# ESP32-S3 register map
Vendor: ESPRESSIF SYSTEMS (SHANGHAI) CO., LTD.; Series: ESP32 S-Series; File version: 22
CPU: Xtensa LX7 r0p0, little endian, no MPU, FPU, 0 interrupt priority bits
Address unit: 32 bits
Registers are 32-bit, read-write, reset 0x0 unless marked. A register's access mark holds for its fields unless they carry their own. Offsets are from the block's base; [hi:lo] are bit positions; {n}, {i} and the like mark numbered series.

## GPIO — General Purpose Input/Output
Base 0x60004000
0x00 BT_SELECT — GPIO bit select register
  [31:0] BT_SEL
0x04 OUT — GPIO output register for GPIO0-31
  [31:0] DATA_ORIG
0x08 OUT_W1TS wo — GPIO output set register for GPIO0-31
0x0C OUT_W1TC wo — GPIO output clear register for GPIO0-31
0x10 OUT1 — GPIO output register for GPIO32-53
  [21:0] DATA_ORIG
0x14 OUT1_W1TS wo — GPIO output set register for GPIO32-53
  [21:0] OUT1_W1TS
0x18 OUT1_W1TC wo — GPIO output clear register for GPIO32-53
  [21:0] OUT1_W1TC
0x1C SDIO_SELECT — GPIO sdio select register
  [7:0] SDIO_SEL
0x20 ENABLE — GPIO output enable register for GPIO0-31
  [31:0] DATA
0x24 ENABLE_W1TS wo — GPIO output enable set register for GPIO0-31
0x28 ENABLE_W1TC wo — GPIO output enable clear register for GPIO0-31
0x2C ENABLE1 — GPIO output enable register for GPIO32-53
  [21:0] DATA
0x30 ENABLE1_W1TS wo — GPIO output enable set register for GPIO32-53
  [21:0] ENABLE1_W1TS
0x34 ENABLE1_W1TC wo — GPIO output enable clear register for GPIO32-53
  [21:0] ENABLE1_W1TC
0x38 STRAP ro — pad strapping register
  [15:0] STRAPPING
0x3C IN ro — GPIO input register for GPIO0-31
  [31:0] DATA_NEXT
0x40 IN1 ro — GPIO input register for GPIO32-53
  [21:0] DATA_NEXT
0x44 STATUS — GPIO interrupt status register for GPIO0-31
  [31:0] INTERRUPT
0x48 STATUS_W1TS wo — GPIO interrupt status set register for GPIO0-31
0x4C STATUS_W1TC wo — GPIO interrupt status clear register for GPIO0-31
0x50 STATUS1 — GPIO interrupt status register for GPIO32-53
  [21:0] INTERRUPT
0x54 STATUS1_W1TS wo — GPIO interrupt status set register for GPIO32-53
  [21:0] STATUS1_W1TS
0x58 STATUS1_W1TC wo — GPIO interrupt status clear register for GPIO32-53
  [21:0] STATUS1_W1TC
0x5C PCPU_INT ro — GPIO PRO_CPU interrupt status register for GPIO0-31
  [31:0] PROCPU_INT
0x60 PCPU_NMI_INT ro — GPIO PRO_CPU(not shielded) interrupt status register for GPIO0-31
  [31:0] PROCPU_NMI_INT
0x64 CPUSDIO_INT ro — GPIO CPUSDIO interrupt status register for GPIO0-31
  [31:0] SDIO_INT
0x68 PCPU_INT1 ro — GPIO PRO_CPU interrupt status register for GPIO32-53
  [21:0] PROCPU_INT1
0x6C PCPU_NMI_INT1 ro — GPIO PRO_CPU(not shielded) interrupt status register for GPIO32-53
  [21:0] PROCPU_NMI_INT1
0x70 CPUSDIO_INT1 ro — GPIO CPUSDIO interrupt status register for GPIO32-53
  [21:0] SDIO_INT1
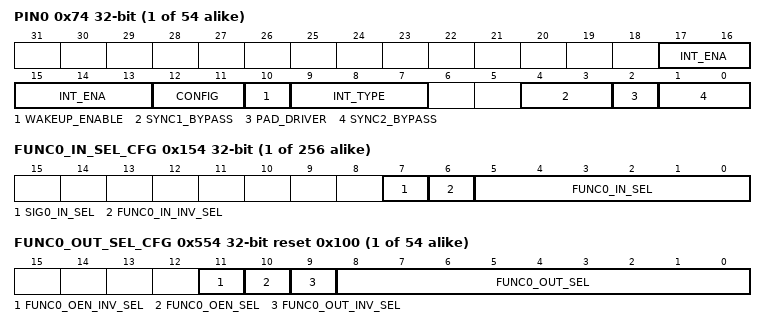
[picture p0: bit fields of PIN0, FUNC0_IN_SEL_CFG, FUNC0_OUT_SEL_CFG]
{0x74+4i} PIN{i} (i=0..53) — GPIO pin configuration register
  [17:13] INT_ENA — set bit 13 to enable CPU interrupt. set bit 14 to enable CPU(not shielded) interrupt.
  [12:11] CONFIG — reserved
  [10] WAKEUP_ENABLE — set this bit to enable GPIO wakeup.(can only wakeup CPU from Light-sleep Mode)
  [9:7] INT_TYPE — set this value to choose interrupt mode. 0:disable GPIO interrupt. 1:trigger at posedge. 2:trigger at negedge. 3:trigger at any edge. 4:valid at low level. 5:valid at high level
  [4:3] SYNC1_BYPASS — set GPIO input_sync1 signal mode. 0:disable. 1:trigger at negedge. 2or3:trigger at posedge.
  [2] PAD_DRIVER — set this bit to select pad driver. 1:open-drain. 0:normal.
  [1:0] SYNC2_BYPASS — set GPIO input_sync2 signal mode. 0:disable. 1:trigger at negedge. 2or3:trigger at posedge.
0x14C STATUS_NEXT ro — GPIO interrupt source register for GPIO0-31
  [31:0] STATUS_INTERRUPT_NEXT
0x150 STATUS_NEXT1 ro — GPIO interrupt source register for GPIO32-53
  [21:0] STATUS_INTERRUPT_NEXT1
{0x154+4i} FUNC{i}_IN_SEL_CFG (i=0..255) — GPIO input function configuration register
  [7] SIG{i}_IN_SEL — set this bit to bypass GPIO. 1:do not bypass GPIO. 0:bypass GPIO.
  [6] FUNC{i}_IN_INV_SEL — set this bit to invert input signal. 1:invert. 0:not invert.
  [5:0] FUNC{i}_IN_SEL — set this value: s=0-53: connect GPIO[s] to this port. s=0x38: set this port always high level. s=0x3C: set this port always low level.
{0x554+4i} FUNC{i}_OUT_SEL_CFG reset 0x100 (i=0..53) — GPIO output function select register
  [11] FUNC{i}_OEN_INV_SEL — set this bit to invert output enable signal.1:invert.0:not invert.
  [10] FUNC{i}_OEN_SEL — set this bit to select output enable signal.1:use GPIO_ENABLE_REG[n] as output enable signal.0:use peripheral output enable signal.
  [9] FUNC{i}_OUT_INV_SEL — set this bit to invert output signal.1:invert.0:not invert.
  [8:0] FUNC{i}_OUT_SEL — The value of the bits: 0<=s<=256. Set the value to select output signal. s=0-255: output of GPIO[n] equals input of peripheral[s]. s=256: output of GPIO[n] equals GPIO_OUT_REG[n].
0x62C CLOCK_GATE reset 0x1 — GPIO clock gate register
  [0] CLK_EN — set this bit to enable GPIO clock gate
0x6FC REG_DATE reset 0x1907040 — GPIO version register
  [27:0] REG_DATE — version register
